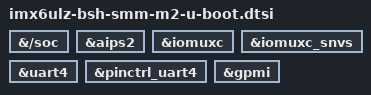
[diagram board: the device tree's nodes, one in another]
// SPDX-License-Identifier: GPL-2.0
/*
 * Copyright (C) 2022 BSH Hausgeraete GmbH
 *
 * Author: Michael Trimarchi <michael@amarulasolutions.com>
 */

&{/soc} {
	bootph-all;
};

&aips2 {
	bootph-all;
};

&iomuxc {
	bootph-all;
};

&iomuxc_snvs {
	bootph-all;
};

&uart4 {
	bootph-all;
};

&pinctrl_uart4 {
	bootph-all;
};

&gpmi {
	bootph-pre-ram;
	bootph-all;
};
